# CTRL_MMR0_CFG0 register map
Vendor: Texas Instruments
Registers are 32-bit, read-write, reset 0x0 unless marked. A register's access mark holds for its fields unless they carry their own. Offsets are as the file gives them; [hi:lo] are bit positions; {n}, {i} and the like mark numbered series; 'fields as' and 'values as' point back to an identical list.

## CTRL_MMR0_CFG0 (part 7 of 10)
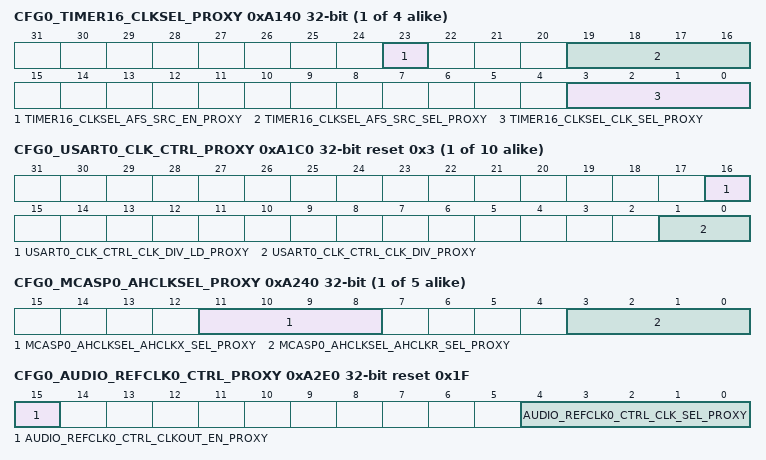
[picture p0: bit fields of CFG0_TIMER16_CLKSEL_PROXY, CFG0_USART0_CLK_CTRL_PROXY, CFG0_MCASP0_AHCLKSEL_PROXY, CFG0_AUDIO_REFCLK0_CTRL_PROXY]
{0xA100+4i} CFG0_TIMER{i}_CLKSEL_PROXY (i=16..19) — Timer{i} functional clock selection control
  [23] TIMER{i}_CLKSEL_AFS_SRC_EN_PROXY — Enable AFS source mux output as the Timer clock source. Note that for TIMER17 and TIMER19 this selection will be overridden if cascade_en in the associated TIMERn_CTRL register is set. 0 - Use functional clock selected by clk_sel value 1 - Use AFS input selected by afs_src_sel value
  [19:16] TIMER{i}_CLKSEL_AFS_SRC_SEL_PROXY — Selects the ASFR/AFSX input to use as a timer clock when afs_src_en is set. Field values (Others are reserved): 4'b0000 - McASP0_AFSR 4'b0001 - McASP0_AFSX 4'b0010 - McASP1_AFSR 4'b0011 - McASP1_AFSX 4'b0100 - McASP2_AFSR 4'b0101 - McASP2_AFSX 4'b0110 - McASP3_AFSR 4'b0111 - McASP3_AFSX 4'b1000 - McASP4_AFSR 4'b1001 - McASP4_AFSX 4'b1010 - 0 4'b1011 - 0 4'b1100 - 0 4'b1101 - 0 4'b1110 - 0 4'b1111 - 0
  [3:0] TIMER{i}_CLKSEL_CLK_SEL_PROXY — Timer functional clock input select mux control (Reserved values default to HFOSC1_CLK) Field values (Others are reserved): 4'b0000 - HFOSC0_CLKOUT 4'b0001 - HFOSC1_CLKOUT 4'b0010 - MAIN_PLL0_HSDIV1_CLKOUT 4'b0011 - CLK_12M_RC 4'b0100 - MAIN_PLL3_HSDIV3_CLKOUT 4'b0101 - MCU_EXT_REFCLK0 (pin) 4'b0110 - EXT_REFCLK1 (pin) 4'b0111 - LFXOSC_CLKOUT 4'b1000 - CPTS_RFT_CLK (pin) 4'b1001 - MAIN_PLL1_HSDIV3_CLKOUT 4'b1010 - MAIN_PLL2_HSDIV6_CLKOUT 4'b1011 - MAIN_PLL4_HSDIV2_CLKOUT 4'b1100 - CPTS_GENF2 4'b1101 - CPTS_GENF3 4'b1110 - CPSW2G_CPTS_GENF0 4'b1111 - CPSW9G_CPTS_GENF0
{0xA190+4i} CFG0_SPI{i}_CLKSEL_PROXY (i=0..3) — SPI{i} clock control
  [16] SPI{i}_CLKSEL_MSTR_LB_CLKSEL_PROXY — Master mode receive capture clock loopback selection 1'b0 - Internal clock loopback 1'b1 - Loopback from pad
{0xA190+4i} CFG0_SPI{i}_CLKSEL_PROXY (i=5..7) — SPI{i} clock control
  fields as CFG0_SPI0_CLKSEL_PROXY
{0xA1C0+4i} CFG0_USART{i}_CLK_CTRL_PROXY reset 0x3 (i=0..9) — Selects the clock divider of the USART{i} functional clock
  [16] USART{i}_CLK_CTRL_CLK_DIV_LD_PROXY — Load the output divider valueWriting 1 to this bit will generate a load pulse to load the USART{i} clock programmable divider value. This bit can be cleared but must not be set in the same write cycle in which the clk_div value is changed.
  [1:0] USART{i}_CLK_CTRL_CLK_DIV_PROXY — Selects the clock divider value. Supports divide values of 1 to 4 Default is /4. To load the new divider value the clk_div_ld bit must be cleared and then set to 1. Field values (Others are reserved): 2'b00 - Divide by 1 2'b01 - Divide by 2 2'b10 - Divide by 3 2'b11 - Divide by 4
{0xA200+4i} CFG0_MCASP{i}_CLKSEL_PROXY (i=0..4) — Selects the functional clock source for McASP{i}
  [2:0] MCASP{i}_CLKSEL_AUXCLK_SEL_PROXY — Selects the McASP{i} auxclk clock source Reserved values default to HFOSC1_CLK Field values (Others are reserved): 3'b000 - MAIN_PLL4_HSDIV0_CLKOUT 3'b001 - MAIN_PLL2_HSDIV2_CLKOUT 3'b010 - 0 3'b011 - 0 3'b100 - ATCLK0 3'b101 - ATCLK1 3'b110 - ATCLK2 3'b111 - ATCLK3
{0xA240+4i} CFG0_MCASP{i}_AHCLKSEL_PROXY (i=0..4) — Selects the AHCLKX and AHCLKR clock source for McASP{i}
  [11:8] MCASP{i}_AHCLKSEL_AHCLKX_SEL_PROXY — Selects the AHCLKX input source for McASP{i} Field values (Others are reserved): 4'b0000 - HFOSC1_CLKOUT 4'b0001 - HFOSC0_CLKOUT 4'b0010 - AUDIO_EXT_REFCLK0_IN 4'b0011 - AUDIO_EXT_REFCLK1_IN 4'b0100 - 0 4'b0101 - 0 4'b0110 - 0 4'b0111 - 0 4'b1000 - ATCLK0 4'b1001 - ATCLK1 4'b1010 - ATCLK2 4'b1011 - ATCLK3
  [3:0] MCASP{i}_AHCLKSEL_AHCLKR_SEL_PROXY — Selects the AHCLKR input source for McASP{i} Field values (Others are reserved): 4'b0000 - HFOSC1_CLKOUT 4'b0001 - HFOSC0_CLKOUT 4'b0010 - AUDIO_EXT_REFCLK0_IN 4'b0011 - AUDIO_EXT_REFCLK1_IN 4'b0100 - 0 4'b0101 - 0 4'b0110 - 0 4'b0111 - 0 4'b1000 - ATCLK0 4'b1001 - ATCLK1 4'b1010 - ATCLK2 4'b1011 - ATCLK3 4'b1100 - 0 4'b1101 - 0 4'b1110 - 0 4'b1111 - 0
{0xA2A0+4i} CFG0_ATL_BWS{i}_SEL_PROXY (i=0..3) — Selects the source of ATL Baseband Word Select {i}
  [4:0] ATL_BWS{i}_SEL_WD_SEL_PROXY — BWS source signal Field values (Others are reserved): 5'b00000 - McASP0 AFSR Pin Input 5'b00001 - McASP1 AFSR Pin Input 5'b00010 - McASP2 AFSR Pin Input 5'b00011 - McASP3 AFSR Pin Input 5'b00100 - McASP4 AFSR Pin Input 5'b00101 - 0 5'b00110 - 0 5'b00111 - 0 5'b01000 - 0 5'b01001 - 0 5'b01010 - 0 5'b01011 - 0 5'b01100 - McASP0 AFSX Pin Input 5'b01101 - McASP1 AFSX Pin Input 5'b01110 - McASP2 AFSX Pin Input 5'b01111 - McASP3 AFSX Pin Input 5'b10000 - McASP4 AFSX Pin Input 5'b10001 - 0 5'b10010 - 0 5'b10011 - 0 5'b10100 - 0 5'b10101 - 0 5'b10110 - 0 5'b10111 - 0 5'b11000 - AUDIO_EXT_REFCLK0 Pin input 5'b11001 - AUDIO_EXT_REFCLK1 Pin input 5'b11010 - 0 5'b11011 - 0
{0xA2B0+4i} CFG0_ATL_AWS{i}_SEL_PROXY (i=0..3) — Selects the source of ATL Audio Word Select {i}
  [4:0] ATL_AWS{i}_SEL_WD_SEL_PROXY — AWS source signal Field values (Others are reserved): 5'b00000 - McASP0 AFSX Pin Input 5'b00001 - McASP1 AFSX Pin Input 5'b00010 - McASP2 AFSX Pin Input 5'b00011 - McASP3 AFSX Pin Input 5'b00100 - McASP4 AFSX Pin Input 5'b00101 - 0 5'b00110 - 0 5'b00111 - 0 5'b01000 - 0 5'b01001 - 0 5'b01010 - 0 5'b01011 - 0 5'b01100 - McASP0 AFSX Pin Input 5'b01101 - McASP1 AFSX Pin Input 5'b01110 - McASP2 AFSX Pin Input 5'b01111 - McASP3 AFSX Pin Input 5'b10000 - McASP4 AFSX Pin Input 5'b10001 - 0 5'b10010 - 0 5'b10011 - 0 5'b10100 - 0 5'b10101 - 0 5'b10110 - 0 5'b10111 - 0 5'b11000 - AUDIO_EXT_REFCLK0 Pin input 5'b11001 - AUDIO_EXT_REFCLK1 Pin input 5'b11010 - 0 5'b11011 - 0 5'b11100 - 0 5'b11101 - 0
0xA2C0 CFG0_ATL_CLKSEL_PROXY — Selects the source of the ATL PCLK
  [3:0] ATL_CLKSEL_PCLK_SEL_PROXY — Selects the PCLK clock source Field values (Others are reserved): 3'b000 - MAIN_PLL4_HSDIV1_CLKOUT 3'b001 - MAIN_PLL2_HSDIV2_CLKOUT 3'b010 - 0 3'b011 - 0 3'b100 - MAIN_PLL0_HSDIV7_CLKOUT 3'b101 - MCU_EXT_REFCLK0 (pin) 3'b110 - EXT_REFCLK1 (pin) 3'b111 - 0
0xA2E0 CFG0_AUDIO_REFCLK0_CTRL_PROXY reset 0x1F — Selects the clock source for the AUDIO_EXT_REFCLK0 output
  [15] AUDIO_REFCLK0_CTRL_CLKOUT_EN_PROXY — AUDIO_REFCLK 0 output enableThis bit is inverted to drive the active low output buffer enable 0 - AUDIO_EXT_REFCLK0 pin is configured as an input 1 - AUDIO_EXT_REFCLK0 pin is configured as an output
  [4:0] AUDIO_REFCLK0_CTRL_CLK_SEL_PROXY — Clock source (default selects a tie-off of 0 for no output) Field values (Others are reserved): 5'b00000 - MCASP0 AHCLKR Output 5'b00001 - MCASP1 AHCLKR Output 5'b00010 - MCASP2 AHCLKR Output 5'b00011 - MCASP3 AHCLKR Output 5'b00100 - MCASP4 AHCLKR Output 5'b01100 - MCASP0 AHCLKX Output 5'b01101 - MCASP1 AHCLKX Output 5'b01110 - MCASP2 AHCLKX Output 5'b01111 - MCASP3 AHCLKX Output 5'b10000 - MCASP4 AHCLKX Output 5'b11000 - ATCLK0 5'b11001 - ATCLK1 5'b11010 - ATCLK2 5'b11011 - ATCLK3 5'b11100 - MAIN_PLL4_HSDIV2_CLKOUT 5'b11101 - 0 5'b11110 - 0 5'b11111 - 0
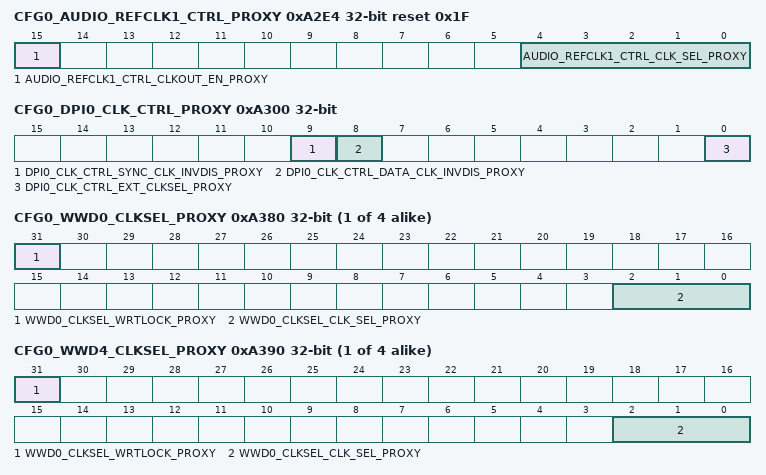
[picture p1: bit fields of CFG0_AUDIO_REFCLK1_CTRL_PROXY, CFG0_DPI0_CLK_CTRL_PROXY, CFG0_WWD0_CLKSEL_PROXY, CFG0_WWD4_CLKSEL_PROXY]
0xA2E4 CFG0_AUDIO_REFCLK1_CTRL_PROXY reset 0x1F — Selects the clock source for the AUDIO_EXT_REFCLK1 output
  [15] AUDIO_REFCLK1_CTRL_CLKOUT_EN_PROXY — AUDIO_REFCLK 1 output enableThis bit is inverted to drive the active low output buffer enable 0 - AUDIO_EXT_REFCLK1 pin is configured as an input 1 - AUDIO_EXT_REFCLK1 pin is configured as an output
  [4:0] AUDIO_REFCLK1_CTRL_CLK_SEL_PROXY — Clock source (default selects a tie-off of 0 for no output) Field values (Others are reserved): 5'b00000 - MCASP0 AHCLKR Output 5'b00001 - MCASP1 AHCLKR Output 5'b00010 - MCASP2 AHCLKR Output 5'b00011 - MCASP3 AHCLKR Output 5'b00100 - MCASP4 AHCLKR Output 5'b01100 - MCASP0 AHCLKX Output 5'b01101 - MCASP1 AHCLKX Output 5'b01110 - MCASP2 AHCLKX Output 5'b01111 - MCASP3 AHCLKX Output 5'b10000 - MCASP4 AHCLKX Output 5'b11000 - ATCLK0 5'b11001 - ATCLK1 5'b11010 - ATCLK2 5'b11011 - ATCLK3 5'b11100 - MAIN_PLL4_HSDIV2_CLKOUT 5'b11101 - 0 5'b11110 - 0 5'b11111 - 0
0xA300 CFG0_DPI0_CLK_CTRL_PROXY — Selects the clock source for the DPI0 video output
  [9] DPI0_CLK_CTRL_SYNC_CLK_INVDIS_PROXY — Clock edge select for DPI0 sync outputs 0 - HSYNC and VSYNC are driven on the falling edge of clk 1 - HSYNC and VSYNC are driven on the rising edge of clkNote that this value should align with the programmed value of the DSS POL_FREQ.RF bitfield.
  [8] DPI0_CLK_CTRL_DATA_CLK_INVDIS_PROXY — Clock edge select for DPI0 data outputs 0 - DATA and DE are driven on the falling edge of clk 1 - DATA and DE are driven on the rising edge of clkNote that this value should align with the programmed value of the DSS POL_FREQ.IPC bitfield.
  [0] DPI0_CLK_CTRL_EXT_CLKSEL_PROXY — Selects whether to use DSS PLL3 or an external pin as a DPI clock source. (See the J7AM Clock Specification for more details.) 0 - Use internal clock : MAIN_PLL19_HSDIV0_CLKOUT 1 - Use external clock : VOUT0_EXTPCLKIN
0xA310 CFG0_DPHY0_CLKSEL_PROXY — Selects the clock source for the DSI0 transmit PHY
  [1:0] DPHY0_CLKSEL_REF_CLK_SEL_PROXY — DPHY reference clock source 2'b00 - HFOSC0_CLKOUT 2'b01 - HFOSC1_CLKOUT 2'b10 - MAIN_PLL3_HSDIV4_CLKOUT 2'b11 - MAIN_PLL2_HSDIV4_CLKOUT
0xA314 CFG0_DPHY1_CLKSEL_PROXY — Selects the clock source for the DSI1 transmit PHY
  [1:0] DPHY1_CLKSEL_REF_CLK_SEL_PROXY — DPHY reference clock source 2'b00 - HFOSC0_CLKOUT 2'b01 - HFOSC1_CLKOUT 2'b10 - MAIN_PLL3_HSDIV4_CLKOUT 2'b11 - MAIN_PLL2_HSDIV4_CLKOUT
0xA324 CFG0_DSS_DISPC0_CLKSEL1_PROXY — Selects the clock source for DPI Lane 1 of Display Controller Instance 0
  [1:0] DSS_DISPC0_CLKSEL1_DPI1_PCLK_PROXY — DPI lane 1 pixel clock source Field values (Others are reserved): 2'b00 - MAIN_PLL17_HSDIV0_CLKOUT 2'b01 - MAIN_PLL19_HSDIV0_CLKOUT_EXTPCLKIN 2'b10 - MAIN_PLL19_HSDIV0_CLKOUT_EXTPCLKIN 2'b11 - MAIN_PLL16_HSDIV0_CLKOUT
0xA328 CFG0_DSS_DISPC0_CLKSEL2_PROXY — Selects the clock source for DPI Lane 2 of Display Controller Instance 0
  [0] DSS_DISPC0_CLKSEL2_DPI2_PCLK_PROXY — DPI lane 2 pixel clock source Field values (Others are reserved): 1'b0 - MAIN_PLL16_HSDIV0_CLKOUT 1'b1 - MAIN_PLL17_HSDIV0_CLKOUT
0xA32C CFG0_DSS_DISPC0_CLKSEL3_PROXY — Can also override the DPI Lane 0 and DPI Lane 2 clock source for certain values.
  [2:0] DSS_DISPC0_CLKSEL3_DPI3_PCLK_PROXY — DPI lane 3 pixel clock sourceNote that values of 3'b1x1 also change the DPI lane 0 pixel clock source and values of 3'b11x change the DPI lane 2 pixel clock source Field values (Others are reserved): 3'b000 - MAIN_PLL16_HSDIV1_CLKOUT 3'b001 - MAIN_PLL17_HSDIV1_CLKOUT 3'b010 - MAIN_PLL17_HSDIV1_CLKOUT 3'b011 - MAIN_PLL19_HSDIV0_CLKOUT_EXTPCLKIN 3'b100 - MAIN_PLL19_HSDIV0_CLKOUT_EXTPCLKIN 3'b101 - MAIN_PLL19_HSDIV0_CLKOUT_EXTPCLKIN and dpi0_pclk = dpi1_pclk 3'b110 - MAIN_PLL19_HSDIV0_CLKOUT_EXTPCLKIN and dpi2_pclk = MAIN_PLL19_HSDIV0_CLKOUT_EXTPCLKIN 3'b111 - MAIN_PLL19_HSDIV0_CLKOUT_EXTPCLKIN and dpi0_pclk = dpi1_pclk and dpi2_pclk = MAIN_PLL19_HSDIV0_CLKOUT_EXTPCLKIN
0xA350 CFG0_EDP0_CLK_CTRL_PROXY — Controls clock operation for Embedded Display Port 0
  [8] EDP0_CLK_CTRL_DSI_CLK_DYN_SWTCH_DIS_PROXY — EDP0 DSI clock dynamic switch disable.This bit controls whether the EDP source clock is dynamically switched (to MAIN_PLL2_HSDIV7_CLKOUT) on a warm reset event. (See PLL Bypass Logic during Main WarmReset details in the Reset MicroArch Specification). This bit only applies if eDP reset isolation is enabled. 0 - Dynamic switching on warm reset is enabled 1 - Dynamic switching on warm reset is disabled
{0xA380+4i} CFG0_WWD{i}_CLKSEL_PROXY (i=0..3) — ARM MPU Cluster 0 Core {i} Windowed watchdog timer functional clock selection control
  [31] WWD{i}_CLKSEL_WRTLOCK_PROXY — When set, locks WWD{i}_CLKSEL from further writes until the next module reset.
  [2:0] WWD{i}_CLKSEL_CLK_SEL_PROXY — Windowed watchdog timer functional clock input select mux control Field values (Others are reserved): 3'b000 - HFOSC0_CLKOUT 3'b001 - LFXOSC_CLKOUT 3'b010 - CLK_12M_RC 3'b011 - CLK_32K 3'b100 - HFOSC1_CLKOUT 3'b101 - reserved (HFOSC1_CLKOUT) 3'b110 - reserved (HFOSC1_CLKOUT) 3'b111 - reserved (HFOSC1_CLKOUT)
{0xA380+4i} CFG0_WWD{i}_CLKSEL_PROXY (i=4..7) — ARM MPU Cluster 1 Core {i-4} Windowed watchdog timer functional clock selection control
  fields as CFG0_WWD0_CLKSEL_PROXY
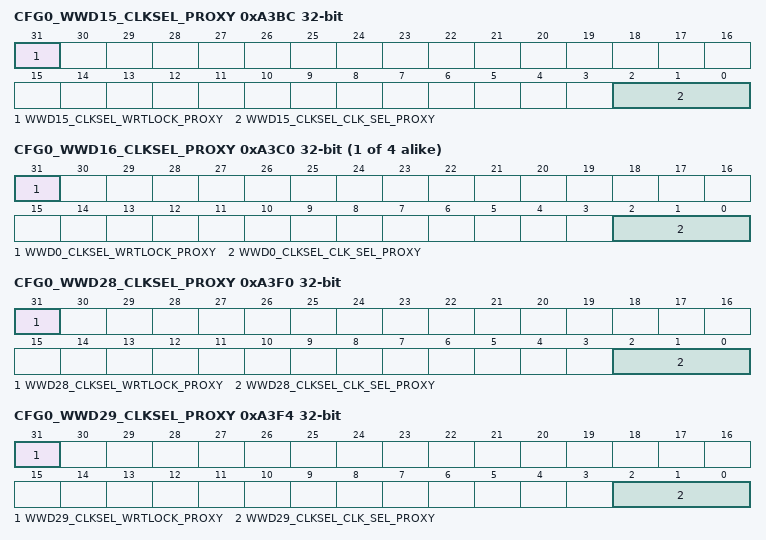
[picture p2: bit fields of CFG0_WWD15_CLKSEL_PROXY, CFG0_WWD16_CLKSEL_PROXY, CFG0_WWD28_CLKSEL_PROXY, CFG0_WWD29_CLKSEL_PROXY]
0xA3BC CFG0_WWD15_CLKSEL_PROXY — GPU Windowed watchdog timer functional clock selection control
  [31] WWD15_CLKSEL_WRTLOCK_PROXY — When set, locks WWD15_CLKSEL from further writes until the next module reset.
  [2:0] WWD15_CLKSEL_CLK_SEL_PROXY — Windowed watchdog timer functional clock input select mux control Field values (Others are reserved): 3'b000 - HFOSC0_CLKOUT 3'b001 - LFXOSC_CLKOUT 3'b010 - CLK_12M_RC 3'b011 - CLK_32K 3'b100 - HFOSC1_CLKOUT 3'b101 - reserved (HFOSC1_CLKOUT) 3'b110 - reserved (HFOSC1_CLKOUT) 3'b111 - reserved (HFOSC1_CLKOUT)
{0xA380+4i} CFG0_WWD{i}_CLKSEL_PROXY (i=16..19) — C71x Core {i-16} Windowed watchdog timer functional clock selection control
  fields as CFG0_WWD0_CLKSEL_PROXY
0xA3F0 CFG0_WWD28_CLKSEL_PROXY — Main R5 Clstr0 Core0 Windowed watchdog timer functional clock selection control.
  [31] WWD28_CLKSEL_WRTLOCK_PROXY — When set, locks WWD28_CLKSEL from further writes until the next module reset.
  [2:0] WWD28_CLKSEL_CLK_SEL_PROXY — Windowed watchdog timer functional clock input select mux controlThese bits are warm reset isolated to preserve R5 RTI clock selection. Field values (Others are reserved): 3'b000 - HFOSC0_CLKOUT 3'b001 - LFXOSC_CLKOUT 3'b010 - CLK_12M_RC 3'b011 - CLK_32K 3'b100 - HFOSC1_CLKOUT 3'b101 - reserved (HFOSC1_CLKOUT) 3'b110 - reserved (HFOSC1_CLKOUT) 3'b111 - reserved (HFOSC1_CLKOUT)
0xA3F4 CFG0_WWD29_CLKSEL_PROXY — Main R5 Clstr0 Core1 Windowed watchdog timer functional clock selection control.
  [31] WWD29_CLKSEL_WRTLOCK_PROXY — When set, locks WWD29_CLKSEL from further writes until the next module reset.
  [2:0] WWD29_CLKSEL_CLK_SEL_PROXY — Windowed watchdog timer functional clock input select mux controlThese bits are warm reset isolated to preserve R5 RTI clock selection. Field values (Others are reserved): 3'b000 - HFOSC0_CLKOUT 3'b001 - LFXOSC_CLKOUT 3'b010 - CLK_12M_RC 3'b011 - CLK_32K 3'b100 - HFOSC1_CLKOUT 3'b101 - reserved (HFOSC1_CLKOUT) 3'b110 - reserved (HFOSC1_CLKOUT) 3'b111 - reserved (HFOSC1_CLKOUT)
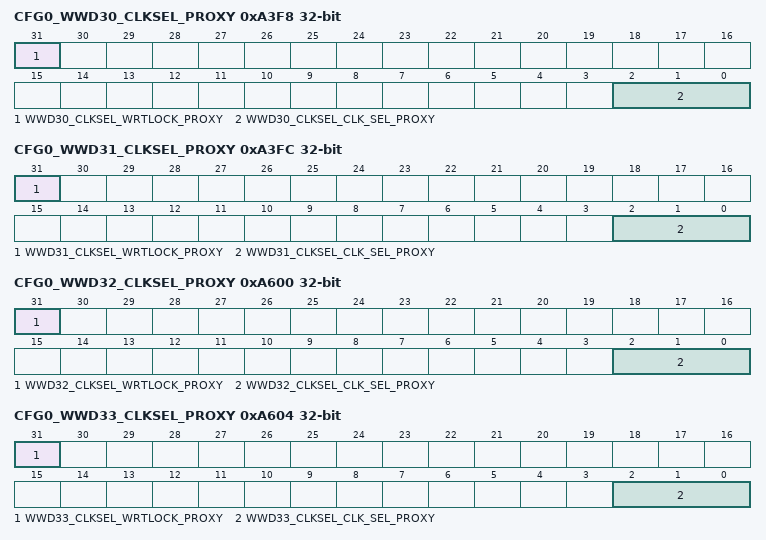
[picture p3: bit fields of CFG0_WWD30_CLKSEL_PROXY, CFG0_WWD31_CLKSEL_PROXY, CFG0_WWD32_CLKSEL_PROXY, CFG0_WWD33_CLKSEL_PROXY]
0xA3F8 CFG0_WWD30_CLKSEL_PROXY — Main R5 Clstr1 Core0 Windowed watchdog timer functional clock selection control.
  [31] WWD30_CLKSEL_WRTLOCK_PROXY — When set, locks WWD30_CLKSEL from further writes until the next module reset.
  [2:0] WWD30_CLKSEL_CLK_SEL_PROXY — Windowed watchdog timer functional clock input select mux controlThese bits are warm reset isolated to preserve R5 RTI clock selection. Field values (Others are reserved): 3'b000 - HFOSC0_CLKOUT 3'b001 - LFXOSC_CLKOUT 3'b010 - CLK_12M_RC 3'b011 - CLK_32K 3'b100 - HFOSC1_CLKOUT 3'b101 - reserved (HFOSC1_CLKOUT) 3'b110 - reserved (HFOSC1_CLKOUT) 3'b111 - reserved (HFOSC1_CLKOUT)
0xA3FC CFG0_WWD31_CLKSEL_PROXY — Main R5 Clstr1 Core1 Windowed watchdog timer functional clock selection control.
  [31] WWD31_CLKSEL_WRTLOCK_PROXY — When set, locks WWD31_CLKSEL from further writes until the next module reset.
  [2:0] WWD31_CLKSEL_CLK_SEL_PROXY — Windowed watchdog timer functional clock input select mux controlThese bits are warm reset isolated to preserve R5 RTI clock selection. Field values (Others are reserved): 3'b000 - HFOSC0_CLKOUT 3'b001 - LFXOSC_CLKOUT 3'b010 - CLK_12M_RC 3'b011 - CLK_32K 3'b100 - HFOSC1_CLKOUT 3'b101 - reserved (HFOSC1_CLKOUT) 3'b110 - reserved (HFOSC1_CLKOUT) 3'b111 - reserved (HFOSC1_CLKOUT)
{0xA400+0x10*i} CFG0_SERDES{i}_CLKSEL_PROXY (i=0..2) — Selects the clock source for Serdes{i}.
  [1:0] SERDES{i}_CLKSEL_CORE_REFCLK_SEL_PROXY — Selects the source for the core_refclk input Field values (Others are reserved): 2'b00 - HFOSC0_CLKOUT 2'b01 - HFOSC1_CLKOUT 2'b10 - MAIN_PLL3_HSDIV4_CLKOUT 2'b11 - MAIN_PLL2_HSDIV4_CLKOUT
0xA440 CFG0_SERDES4_CLKSEL_PROXY — Selects the clock source for Serdes4.
  [1:0] SERDES4_CLKSEL_CORE_REFCLK_SEL_PROXY — Selects the source for the core_refclk input Field values (Others are reserved): 2'b00 - HFOSC0_CLKOUT 2'b01 - HFOSC1_CLKOUT 2'b10 - MAIN_PLL3_HSDIV4_CLKOUT 2'b11 - MAIN_PLL2_HSDIV4_CLKOUT
{0xA480+4i} CFG0_MCAN{i}_CLKSEL_PROXY (i=0..17) — Controls the functional clock source MCAN{i}
  [1:0] MCAN{i}_CLKSEL_CLK_SEL_PROXY — MAIN MCAN_CLK selection 2'b00 - MAIN_PLL0_HSDIV4_CLKOUT 2'b01 - MCU_EXT_REFCLK0 (pin) 2'b10 - HFOSC1_CLKOUT 2'b11 - HFOSC0_CLKOUT
0xA600 CFG0_WWD32_CLKSEL_PROXY — Main R5 Clstr2 Core0 Windowed watchdog timer functional clock selection control.
  [31] WWD32_CLKSEL_WRTLOCK_PROXY — When set, locks WWD32_CLKSEL from further writes until the next module reset.
  [2:0] WWD32_CLKSEL_CLK_SEL_PROXY — Windowed watchdog timer functional clock input select mux controlThese bits are warm reset isolated to preserve R5 RTI clock selection. Field values (Others are reserved): 3'b000 - HFOSC0_CLKOUT 3'b001 - LFXOSC_CLKOUT 3'b010 - CLK_12M_RC 3'b011 - CLK_32K 3'b100 - HFOSC1_CLKOUT 3'b101 - reserved (HFOSC1_CLKOUT) 3'b110 - reserved (HFOSC1_CLKOUT) 3'b111 - reserved (HFOSC1_CLKOUT)
0xA604 CFG0_WWD33_CLKSEL_PROXY — Main R5 Clstr2 Core1 Windowed watchdog timer functional clock selection control.
  [31] WWD33_CLKSEL_WRTLOCK_PROXY — When set, locks WWD33_CLKSEL from further writes until the next module reset.
  [2:0] WWD33_CLKSEL_CLK_SEL_PROXY — Windowed watchdog timer functional clock input select mux controlThese bits are warm reset isolated to preserve R5 RTI clock selection. Field values (Others are reserved): 3'b000 - HFOSC0_CLKOUT 3'b001 - LFXOSC_CLKOUT 3'b010 - CLK_12M_RC 3'b011 - CLK_32K 3'b100 - HFOSC1_CLKOUT 3'b101 - reserved (HFOSC1_CLKOUT) 3'b110 - reserved (HFOSC1_CLKOUT) 3'b111 - reserved (HFOSC1_CLKOUT)
{0xB100+4i} CFG0_CLAIMREG_P2_R{i} (i=0..12)
  [31:0] CLAIMREG_P2_R{i} — Claim bits for Partition 2
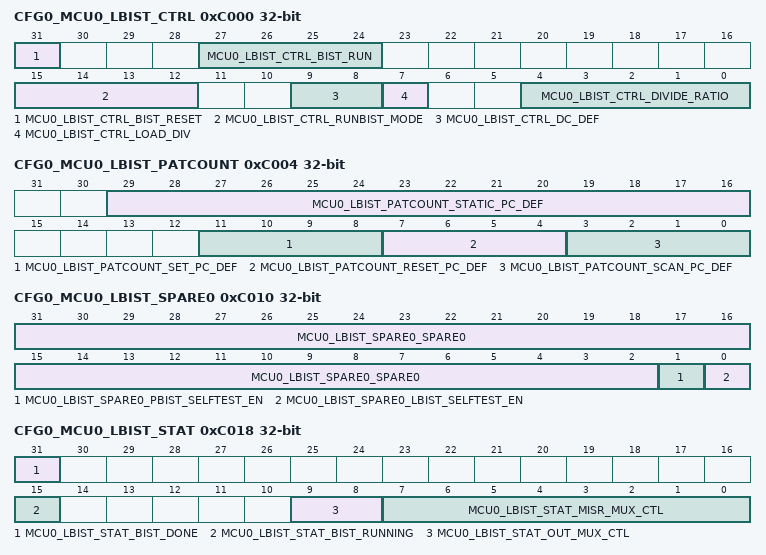
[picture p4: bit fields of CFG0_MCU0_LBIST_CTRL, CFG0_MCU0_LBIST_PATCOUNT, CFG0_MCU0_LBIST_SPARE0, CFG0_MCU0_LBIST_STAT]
0xC000 CFG0_MCU0_LBIST_CTRL — Configures and enables LBIST operation
  [31] MCU0_LBIST_CTRL_BIST_RESET — Reset LBIST macro
  [27:24] MCU0_LBIST_CTRL_BIST_RUN — Starts LBIST if all bits are 1
  [15:12] MCU0_LBIST_CTRL_RUNBIST_MODE — Runbist mode enable if all bits are 1
  [9:8] MCU0_LBIST_CTRL_DC_DEF — Clock delay after scan_enable switching
  [7] MCU0_LBIST_CTRL_LOAD_DIV — Loads LBIST clock divide ratio on transition from 0 to 1
  [4:0] MCU0_LBIST_CTRL_DIVIDE_RATIO — LBIST clock divide ratio
0xC004 CFG0_MCU0_LBIST_PATCOUNT — Specifies the number of LBIST patterns to run
  [29:16] MCU0_LBIST_PATCOUNT_STATIC_PC_DEF — Number of stuck-at patterns to run
  [11:8] MCU0_LBIST_PATCOUNT_SET_PC_DEF — Number of set patterns to run
  [7:4] MCU0_LBIST_PATCOUNT_RESET_PC_DEF — Number of reset patterns to run
  [3:0] MCU0_LBIST_PATCOUNT_SCAN_PC_DEF — Number of chain test patterns to run
0xC008 CFG0_MCU0_LBIST_SEED0 — Specifies the 32 LSBs of the PRPG seed
  [31:0] MCU0_LBIST_SEED0_PRPG_DEF — Initial seed for PRPG (bits 31:0)
0xC00C CFG0_MCU0_LBIST_SEED1 — Specifies the 21 MSBs of the PRPG seed
  [20:0] MCU0_LBIST_SEED1_PRPG_DEF — Initial seed for PRPG (bits 52:32)
0xC010 CFG0_MCU0_LBIST_SPARE0 — Spare LBIST control bits
  [31:2] MCU0_LBIST_SPARE0_SPARE0 — LBIST spare bits
  [1] MCU0_LBIST_SPARE0_PBIST_SELFTEST_EN — PBIST isolation control
  [0] MCU0_LBIST_SPARE0_LBIST_SELFTEST_EN — LBIST isolation control
0xC014 CFG0_MCU0_LBIST_SPARE1 — Spare LBIST control bits
  [31:0] MCU0_LBIST_SPARE1_SPARE1 — LBIST spare bits
0xC018 CFG0_MCU0_LBIST_STAT access per field — Indicates LBIST status and provides MISR selection control
  [31] MCU0_LBIST_STAT_BIST_DONE ro — LBIST is done
  [15] MCU0_LBIST_STAT_BIST_RUNNING ro — LBIST is running
  [9:8] MCU0_LBIST_STAT_OUT_MUX_CTL rw — Selects source of LBIST output 00 - LBIST IP PID value 01 - LBIST CTRL ID value 1x - MISR value
  [7:0] MCU0_LBIST_STAT_MISR_MUX_CTL rw — Selects block of 32 MISR bits to read. A value of 0 selects a compacted 32-bit version of the full MISR. A value of 1-32 select a 32-bit segment of the MISR.
0xC01C CFG0_MCU0_LBIST_MISR ro — Contains LBIST MISR output value
  [31:0] MCU0_LBIST_MISR_MISR_RESULT — 32-bits of MISR value selected by misr_mux_ctl
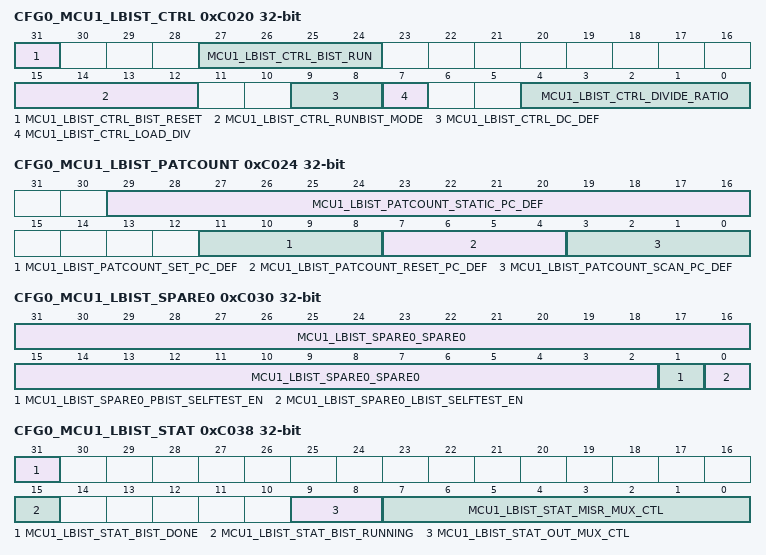
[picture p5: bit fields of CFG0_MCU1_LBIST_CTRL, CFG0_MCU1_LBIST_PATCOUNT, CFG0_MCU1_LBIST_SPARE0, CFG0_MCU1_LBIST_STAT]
0xC020 CFG0_MCU1_LBIST_CTRL — Configures and enables LBIST operation
  [31] MCU1_LBIST_CTRL_BIST_RESET — Reset LBIST macro
  [27:24] MCU1_LBIST_CTRL_BIST_RUN — Starts LBIST if all bits are 1
  [15:12] MCU1_LBIST_CTRL_RUNBIST_MODE — Runbist mode enable if all bits are 1
  [9:8] MCU1_LBIST_CTRL_DC_DEF — Clock delay after scan_enable switching
  [7] MCU1_LBIST_CTRL_LOAD_DIV — Loads LBIST clock divide ratio on transition from 0 to 1
  [4:0] MCU1_LBIST_CTRL_DIVIDE_RATIO — LBIST clock divide ratio
0xC024 CFG0_MCU1_LBIST_PATCOUNT — Specifies the number of LBIST patterns to run
  [29:16] MCU1_LBIST_PATCOUNT_STATIC_PC_DEF — Number of stuck-at patterns to run
  [11:8] MCU1_LBIST_PATCOUNT_SET_PC_DEF — Number of set patterns to run
  [7:4] MCU1_LBIST_PATCOUNT_RESET_PC_DEF — Number of reset patterns to run
  [3:0] MCU1_LBIST_PATCOUNT_SCAN_PC_DEF — Number of chain test patterns to run
0xC028 CFG0_MCU1_LBIST_SEED0 — Specifies the 32 LSBs of the PRPG seed
  [31:0] MCU1_LBIST_SEED0_PRPG_DEF — Initial seed for PRPG (bits 31:0)
0xC02C CFG0_MCU1_LBIST_SEED1 — Specifies the 21 MSBs of the PRPG seed
  [20:0] MCU1_LBIST_SEED1_PRPG_DEF — Initial seed for PRPG (bits 52:32)
0xC030 CFG0_MCU1_LBIST_SPARE0 — Spare LBIST control bits
  [31:2] MCU1_LBIST_SPARE0_SPARE0 — LBIST spare bits
  [1] MCU1_LBIST_SPARE0_PBIST_SELFTEST_EN — PBIST isolation control
  [0] MCU1_LBIST_SPARE0_LBIST_SELFTEST_EN — LBIST isolation control
0xC034 CFG0_MCU1_LBIST_SPARE1 — Spare LBIST control bits
  [31:0] MCU1_LBIST_SPARE1_SPARE1 — LBIST spare bits
0xC038 CFG0_MCU1_LBIST_STAT access per field — Indicates LBIST status and provides MISR selection control
  [31] MCU1_LBIST_STAT_BIST_DONE ro — LBIST is done
  [15] MCU1_LBIST_STAT_BIST_RUNNING ro — LBIST is running
  [9:8] MCU1_LBIST_STAT_OUT_MUX_CTL rw — Selects source of LBIST output 00 - LBIST IP PID value 01 - LBIST CTRL ID value 1x - MISR value
  [7:0] MCU1_LBIST_STAT_MISR_MUX_CTL rw — Selects block of 32 MISR bits to read. A value of 0 selects a compacted 32-bit version of the full MISR. A value of 1-32 select a 32-bit segment of the MISR.
0xC03C CFG0_MCU1_LBIST_MISR ro — Contains LBIST MISR output value
  [31:0] MCU1_LBIST_MISR_MISR_RESULT — 32-bits of MISR value selected by misr_mux_ctl
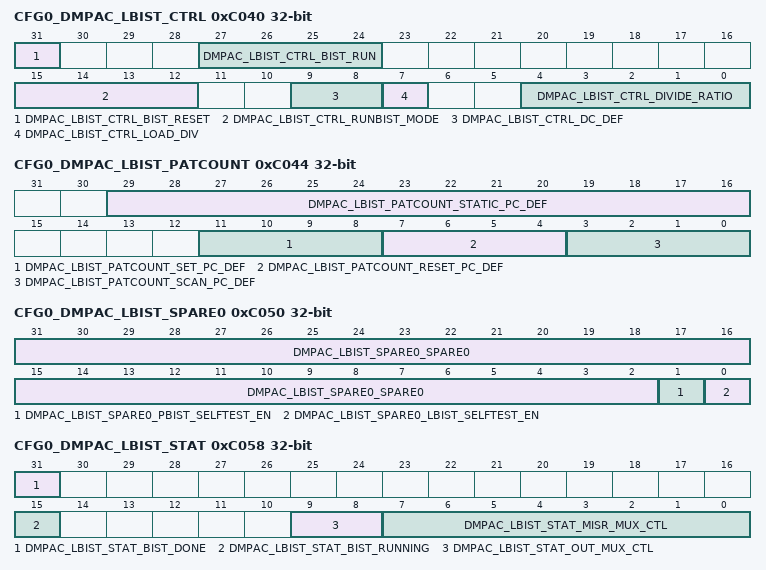
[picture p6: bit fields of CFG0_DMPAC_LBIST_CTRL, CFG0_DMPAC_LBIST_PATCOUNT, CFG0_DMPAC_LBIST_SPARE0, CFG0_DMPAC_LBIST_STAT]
0xC040 CFG0_DMPAC_LBIST_CTRL — Configures and enables LBIST operation
  [31] DMPAC_LBIST_CTRL_BIST_RESET — Reset LBIST macro
  [27:24] DMPAC_LBIST_CTRL_BIST_RUN — Starts LBIST if all bits are 1
  [15:12] DMPAC_LBIST_CTRL_RUNBIST_MODE — Runbist mode enable if all bits are 1
  [9:8] DMPAC_LBIST_CTRL_DC_DEF — Clock delay after scan_enable switching
  [7] DMPAC_LBIST_CTRL_LOAD_DIV — Loads LBIST clock divide ratio on transition from 0 to 1
  [4:0] DMPAC_LBIST_CTRL_DIVIDE_RATIO — LBIST clock divide ratio
0xC044 CFG0_DMPAC_LBIST_PATCOUNT — Specifies the number of LBIST patterns to run
  [29:16] DMPAC_LBIST_PATCOUNT_STATIC_PC_DEF — Number of stuck-at patterns to run
  [11:8] DMPAC_LBIST_PATCOUNT_SET_PC_DEF — Number of set patterns to run
  [7:4] DMPAC_LBIST_PATCOUNT_RESET_PC_DEF — Number of reset patterns to run
  [3:0] DMPAC_LBIST_PATCOUNT_SCAN_PC_DEF — Number of chain test patterns to run
0xC048 CFG0_DMPAC_LBIST_SEED0 — Specifies the 32 LSBs of the PRPG seed
  [31:0] DMPAC_LBIST_SEED0_PRPG_DEF — Initial seed for PRPG (bits 31:0)
0xC04C CFG0_DMPAC_LBIST_SEED1 — Specifies the 21 MSBs of the PRPG seed
  [20:0] DMPAC_LBIST_SEED1_PRPG_DEF — Initial seed for PRPG (bits 52:32)
0xC050 CFG0_DMPAC_LBIST_SPARE0 — Spare LBIST control bits
  [31:2] DMPAC_LBIST_SPARE0_SPARE0 — LBIST spare bits
  [1] DMPAC_LBIST_SPARE0_PBIST_SELFTEST_EN — PBIST isolation control
  [0] DMPAC_LBIST_SPARE0_LBIST_SELFTEST_EN — LBIST isolation control
0xC054 CFG0_DMPAC_LBIST_SPARE1 — Spare LBIST control bits
  [31:0] DMPAC_LBIST_SPARE1_SPARE1 — LBIST spare bits
0xC058 CFG0_DMPAC_LBIST_STAT access per field — Indicates LBIST status and provides MISR selection control
  [31] DMPAC_LBIST_STAT_BIST_DONE ro — LBIST is done
  [15] DMPAC_LBIST_STAT_BIST_RUNNING ro — LBIST is running
  [9:8] DMPAC_LBIST_STAT_OUT_MUX_CTL rw — Selects source of LBIST output 00 - LBIST IP PID value 01 - LBIST CTRL ID value 1x - MISR value
  [7:0] DMPAC_LBIST_STAT_MISR_MUX_CTL rw — Selects block of 32 MISR bits to read. A value of 0 selects a compacted 32-bit version of the full MISR. A value of 1-32 select a 32-bit segment of the MISR.
0xC05C CFG0_DMPAC_LBIST_MISR ro — Contains LBIST MISR output value
  [31:0] DMPAC_LBIST_MISR_MISR_RESULT — 32-bits of MISR value selected by misr_mux_ctl
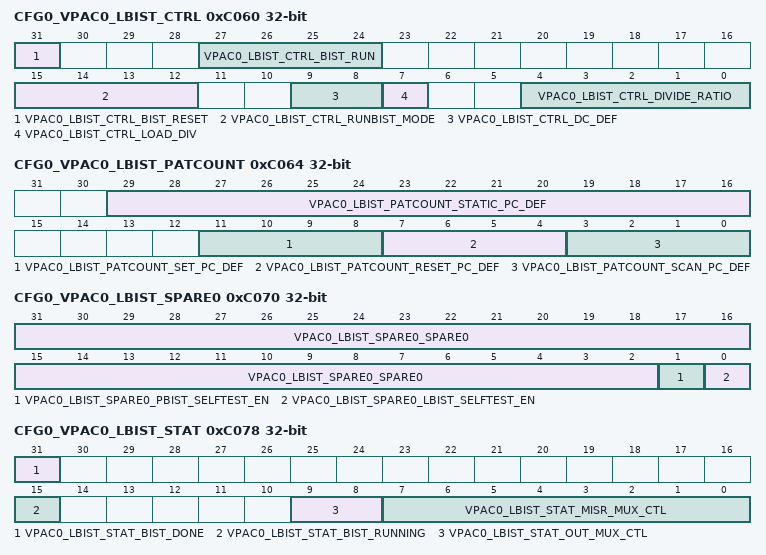
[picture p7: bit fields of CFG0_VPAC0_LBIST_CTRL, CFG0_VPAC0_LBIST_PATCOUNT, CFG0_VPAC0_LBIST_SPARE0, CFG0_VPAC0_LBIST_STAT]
0xC060 CFG0_VPAC0_LBIST_CTRL — Configures and enables LBIST operation
  [31] VPAC0_LBIST_CTRL_BIST_RESET — Reset LBIST macro
  [27:24] VPAC0_LBIST_CTRL_BIST_RUN — Starts LBIST if all bits are 1
  [15:12] VPAC0_LBIST_CTRL_RUNBIST_MODE — Runbist mode enable if all bits are 1
  [9:8] VPAC0_LBIST_CTRL_DC_DEF — Clock delay after scan_enable switching
  [7] VPAC0_LBIST_CTRL_LOAD_DIV — Loads LBIST clock divide ratio on transition from 0 to 1
  [4:0] VPAC0_LBIST_CTRL_DIVIDE_RATIO — LBIST clock divide ratio
0xC064 CFG0_VPAC0_LBIST_PATCOUNT — Specifies the number of LBIST patterns to run
  [29:16] VPAC0_LBIST_PATCOUNT_STATIC_PC_DEF — Number of stuck-at patterns to run
  [11:8] VPAC0_LBIST_PATCOUNT_SET_PC_DEF — Number of set patterns to run
  [7:4] VPAC0_LBIST_PATCOUNT_RESET_PC_DEF — Number of reset patterns to run
  [3:0] VPAC0_LBIST_PATCOUNT_SCAN_PC_DEF — Number of chain test patterns to run
0xC068 CFG0_VPAC0_LBIST_SEED0 — Specifies the 32 LSBs of the PRPG seed
  [31:0] VPAC0_LBIST_SEED0_PRPG_DEF — Initial seed for PRPG (bits 31:0)
0xC06C CFG0_VPAC0_LBIST_SEED1 — Specifies the 21 MSBs of the PRPG seed
  [20:0] VPAC0_LBIST_SEED1_PRPG_DEF — Initial seed for PRPG (bits 52:32)
0xC070 CFG0_VPAC0_LBIST_SPARE0 — Spare LBIST control bits
  [31:2] VPAC0_LBIST_SPARE0_SPARE0 — LBIST spare bits
  [1] VPAC0_LBIST_SPARE0_PBIST_SELFTEST_EN — PBIST isolation control
  [0] VPAC0_LBIST_SPARE0_LBIST_SELFTEST_EN — LBIST isolation control
0xC074 CFG0_VPAC0_LBIST_SPARE1 — Spare LBIST control bits
  [31:0] VPAC0_LBIST_SPARE1_SPARE1 — LBIST spare bits
0xC078 CFG0_VPAC0_LBIST_STAT access per field — Indicates LBIST status and provides MISR selection control
  [31] VPAC0_LBIST_STAT_BIST_DONE ro — LBIST is done
  [15] VPAC0_LBIST_STAT_BIST_RUNNING ro — LBIST is running
  [9:8] VPAC0_LBIST_STAT_OUT_MUX_CTL rw — Selects source of LBIST output 00 - LBIST IP PID value 01 - LBIST CTRL ID value 1x - MISR value
  [7:0] VPAC0_LBIST_STAT_MISR_MUX_CTL rw — Selects block of 32 MISR bits to read. A value of 0 selects a compacted 32-bit version of the full MISR. A value of 1-32 select a 32-bit segment of the MISR.
0xC07C CFG0_VPAC0_LBIST_MISR ro — Contains LBIST MISR output value
  [31:0] VPAC0_LBIST_MISR_MISR_RESULT — 32-bits of MISR value selected by misr_mux_ctl
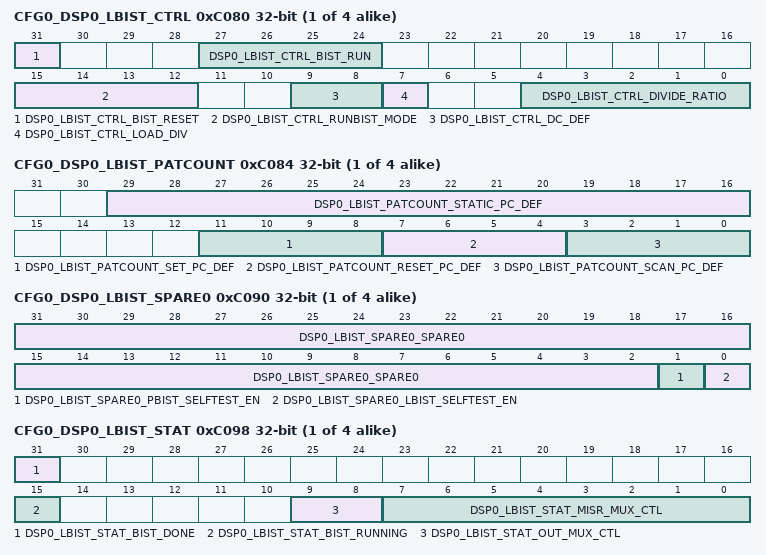
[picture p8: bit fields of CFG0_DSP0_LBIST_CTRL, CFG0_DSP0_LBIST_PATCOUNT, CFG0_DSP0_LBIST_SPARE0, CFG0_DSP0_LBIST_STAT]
{0xC080+0x20*i} CFG0_DSP{i}_LBIST_CTRL (i=0..3) — Configures and enables LBIST operation
  [31] DSP{i}_LBIST_CTRL_BIST_RESET — Reset LBIST macro
  [27:24] DSP{i}_LBIST_CTRL_BIST_RUN — Starts LBIST if all bits are 1
  [15:12] DSP{i}_LBIST_CTRL_RUNBIST_MODE — Runbist mode enable if all bits are 1
  [9:8] DSP{i}_LBIST_CTRL_DC_DEF — Clock delay after scan_enable switching
  [7] DSP{i}_LBIST_CTRL_LOAD_DIV — Loads LBIST clock divide ratio on transition from 0 to 1
  [4:0] DSP{i}_LBIST_CTRL_DIVIDE_RATIO — LBIST clock divide ratio
{0xC084+0x20*i} CFG0_DSP{i}_LBIST_PATCOUNT (i=0..3) — Specifies the number of LBIST patterns to run
  [29:16] DSP{i}_LBIST_PATCOUNT_STATIC_PC_DEF — Number of stuck-at patterns to run
  [11:8] DSP{i}_LBIST_PATCOUNT_SET_PC_DEF — Number of set patterns to run
  [7:4] DSP{i}_LBIST_PATCOUNT_RESET_PC_DEF — Number of reset patterns to run
  [3:0] DSP{i}_LBIST_PATCOUNT_SCAN_PC_DEF — Number of chain test patterns to run
{0xC088+0x20*i} CFG0_DSP{i}_LBIST_SEED0 (i=0..3) — Specifies the 32 LSBs of the PRPG seed
  [31:0] DSP{i}_LBIST_SEED0_PRPG_DEF — Initial seed for PRPG (bits 31:0)
{0xC08C+0x20*i} CFG0_DSP{i}_LBIST_SEED1 (i=0..3) — Specifies the 21 MSBs of the PRPG seed
  [20:0] DSP{i}_LBIST_SEED1_PRPG_DEF — Initial seed for PRPG (bits 52:32)
{0xC090+0x20*i} CFG0_DSP{i}_LBIST_SPARE0 (i=0..3) — Spare LBIST control bits
  [31:2] DSP{i}_LBIST_SPARE0_SPARE0 — LBIST spare bits
  [1] DSP{i}_LBIST_SPARE0_PBIST_SELFTEST_EN — PBIST isolation control
  [0] DSP{i}_LBIST_SPARE0_LBIST_SELFTEST_EN — LBIST isolation control
{0xC094+0x20*i} CFG0_DSP{i}_LBIST_SPARE1 (i=0..3) — Spare LBIST control bits
  [31:0] DSP{i}_LBIST_SPARE1_SPARE1 — LBIST spare bits
{0xC098+0x20*i} CFG0_DSP{i}_LBIST_STAT access per field (i=0..3) — Indicates LBIST status and provides MISR selection control
  [31] DSP{i}_LBIST_STAT_BIST_DONE ro — LBIST is done
  [15] DSP{i}_LBIST_STAT_BIST_RUNNING ro — LBIST is running
  [9:8] DSP{i}_LBIST_STAT_OUT_MUX_CTL rw — Selects source of LBIST output 00 - LBIST IP PID value 01 - LBIST CTRL ID value 1x - MISR value
  [7:0] DSP{i}_LBIST_STAT_MISR_MUX_CTL rw — Selects block of 32 MISR bits to read. A value of 0 selects a compacted 32-bit version of the full MISR. A value of 1-32 select a 32-bit segment of the MISR.
{0xC09C+0x20*i} CFG0_DSP{i}_LBIST_MISR ro (i=0..3) — Contains LBIST MISR output value
  [31:0] DSP{i}_LBIST_MISR_MISR_RESULT — 32-bits of MISR value selected by misr_mux_ctl
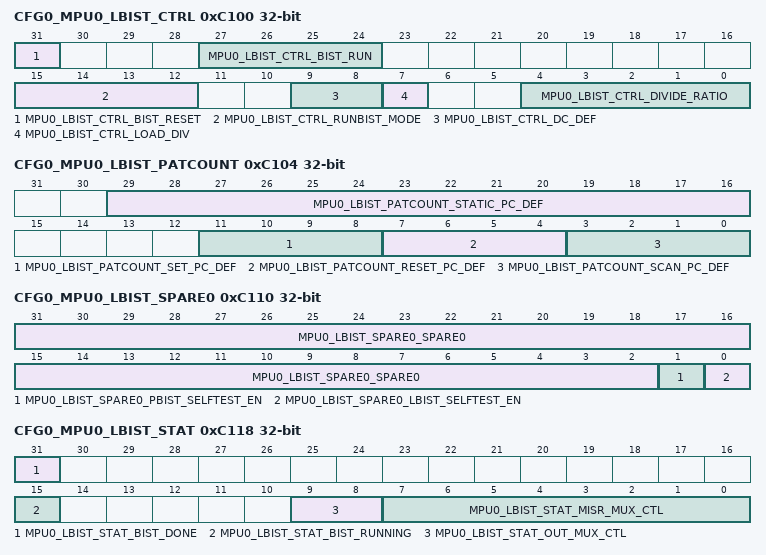
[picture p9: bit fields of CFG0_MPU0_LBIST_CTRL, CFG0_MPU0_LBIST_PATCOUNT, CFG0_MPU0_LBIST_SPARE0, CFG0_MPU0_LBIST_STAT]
0xC100 CFG0_MPU0_LBIST_CTRL — Configures and enables LBIST operation
  [31] MPU0_LBIST_CTRL_BIST_RESET — Reset LBIST macro
  [27:24] MPU0_LBIST_CTRL_BIST_RUN — Starts LBIST if all bits are 1
  [15:12] MPU0_LBIST_CTRL_RUNBIST_MODE — Runbist mode enable if all bits are 1
  [9:8] MPU0_LBIST_CTRL_DC_DEF — Clock delay after scan_enable switching
  [7] MPU0_LBIST_CTRL_LOAD_DIV — Loads LBIST clock divide ratio on transition from 0 to 1
  [4:0] MPU0_LBIST_CTRL_DIVIDE_RATIO — LBIST clock divide ratio
0xC104 CFG0_MPU0_LBIST_PATCOUNT — Specifies the number of LBIST patterns to run
  [29:16] MPU0_LBIST_PATCOUNT_STATIC_PC_DEF — Number of stuck-at patterns to run
  [11:8] MPU0_LBIST_PATCOUNT_SET_PC_DEF — Number of set patterns to run
  [7:4] MPU0_LBIST_PATCOUNT_RESET_PC_DEF — Number of reset patterns to run
  [3:0] MPU0_LBIST_PATCOUNT_SCAN_PC_DEF — Number of chain test patterns to run
0xC108 CFG0_MPU0_LBIST_SEED0 — Specifies the 32 LSBs of the PRPG seed
  [31:0] MPU0_LBIST_SEED0_PRPG_DEF — Initial seed for PRPG (bits 31:0)
0xC10C CFG0_MPU0_LBIST_SEED1 — Specifies the 21 MSBs of the PRPG seed
  [20:0] MPU0_LBIST_SEED1_PRPG_DEF — Initial seed for PRPG (bits 52:32)
0xC110 CFG0_MPU0_LBIST_SPARE0 — Spare LBIST control bits
  [31:2] MPU0_LBIST_SPARE0_SPARE0 — LBIST spare bits
  [1] MPU0_LBIST_SPARE0_PBIST_SELFTEST_EN — PBIST isolation control
  [0] MPU0_LBIST_SPARE0_LBIST_SELFTEST_EN — LBIST isolation control
0xC114 CFG0_MPU0_LBIST_SPARE1 — Spare LBIST control bits
  [31:0] MPU0_LBIST_SPARE1_SPARE1 — LBIST spare bits
0xC118 CFG0_MPU0_LBIST_STAT access per field — Indicates LBIST status and provides MISR selection control
  [31] MPU0_LBIST_STAT_BIST_DONE ro — LBIST is done
  [15] MPU0_LBIST_STAT_BIST_RUNNING ro — LBIST is running
  [9:8] MPU0_LBIST_STAT_OUT_MUX_CTL rw — Selects source of LBIST output 00 - LBIST IP PID value 01 - LBIST CTRL ID value 1x - MISR value
  [7:0] MPU0_LBIST_STAT_MISR_MUX_CTL rw — Selects block of 32 MISR bits to read. A value of 0 selects a compacted 32-bit version of the full MISR. A value of 1-32 select a 32-bit segment of the MISR.
0xC11C CFG0_MPU0_LBIST_MISR ro — Contains LBIST MISR output value
  [31:0] MPU0_LBIST_MISR_MISR_RESULT — 32-bits of MISR value selected by misr_mux_ctl
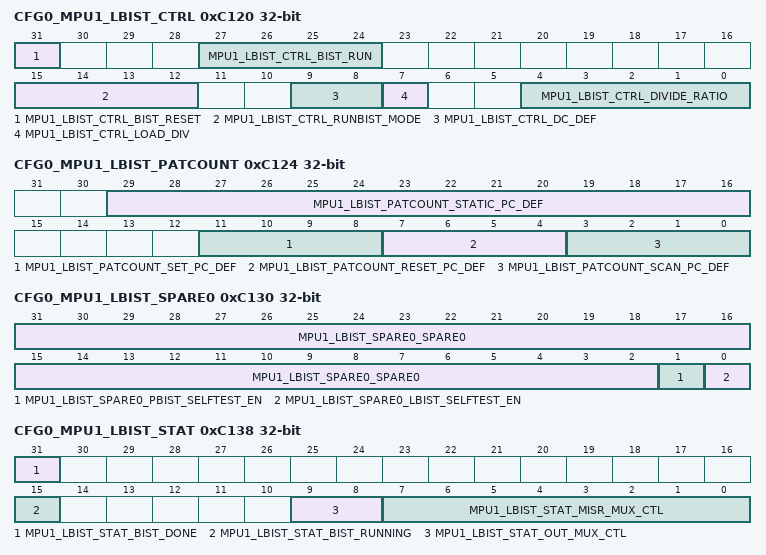
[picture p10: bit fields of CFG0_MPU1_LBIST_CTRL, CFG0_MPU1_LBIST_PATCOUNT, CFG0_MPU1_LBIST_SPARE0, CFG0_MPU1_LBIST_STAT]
0xC120 CFG0_MPU1_LBIST_CTRL — Configures and enables LBIST operation
  [31] MPU1_LBIST_CTRL_BIST_RESET — Reset LBIST macro
  [27:24] MPU1_LBIST_CTRL_BIST_RUN — Starts LBIST if all bits are 1
  [15:12] MPU1_LBIST_CTRL_RUNBIST_MODE — Runbist mode enable if all bits are 1
  [9:8] MPU1_LBIST_CTRL_DC_DEF — Clock delay after scan_enable switching
  [7] MPU1_LBIST_CTRL_LOAD_DIV — Loads LBIST clock divide ratio on transition from 0 to 1
  [4:0] MPU1_LBIST_CTRL_DIVIDE_RATIO — LBIST clock divide ratio
0xC124 CFG0_MPU1_LBIST_PATCOUNT — Specifies the number of LBIST patterns to run
  [29:16] MPU1_LBIST_PATCOUNT_STATIC_PC_DEF — Number of stuck-at patterns to run
  [11:8] MPU1_LBIST_PATCOUNT_SET_PC_DEF — Number of set patterns to run
  [7:4] MPU1_LBIST_PATCOUNT_RESET_PC_DEF — Number of reset patterns to run
  [3:0] MPU1_LBIST_PATCOUNT_SCAN_PC_DEF — Number of chain test patterns to run
0xC128 CFG0_MPU1_LBIST_SEED0 — Specifies the 32 LSBs of the PRPG seed
  [31:0] MPU1_LBIST_SEED0_PRPG_DEF — Initial seed for PRPG (bits 31:0)
0xC12C CFG0_MPU1_LBIST_SEED1 — Specifies the 21 MSBs of the PRPG seed
  [20:0] MPU1_LBIST_SEED1_PRPG_DEF — Initial seed for PRPG (bits 52:32)
0xC130 CFG0_MPU1_LBIST_SPARE0 — Spare LBIST control bits
  [31:2] MPU1_LBIST_SPARE0_SPARE0 — LBIST spare bits
  [1] MPU1_LBIST_SPARE0_PBIST_SELFTEST_EN — PBIST isolation control
  [0] MPU1_LBIST_SPARE0_LBIST_SELFTEST_EN — LBIST isolation control
0xC134 CFG0_MPU1_LBIST_SPARE1 — Spare LBIST control bits
  [31:0] MPU1_LBIST_SPARE1_SPARE1 — LBIST spare bits
0xC138 CFG0_MPU1_LBIST_STAT access per field — Indicates LBIST status and provides MISR selection control
  [31] MPU1_LBIST_STAT_BIST_DONE ro — LBIST is done
  [15] MPU1_LBIST_STAT_BIST_RUNNING ro — LBIST is running
  [9:8] MPU1_LBIST_STAT_OUT_MUX_CTL rw — Selects source of LBIST output 00 - LBIST IP PID value 01 - LBIST CTRL ID value 1x - MISR value
  [7:0] MPU1_LBIST_STAT_MISR_MUX_CTL rw — Selects block of 32 MISR bits to read. A value of 0 selects a compacted 32-bit version of the full MISR. A value of 1-32 select a 32-bit segment of the MISR.
0xC13C CFG0_MPU1_LBIST_MISR ro — Contains LBIST MISR output value
  [31:0] MPU1_LBIST_MISR_MISR_RESULT — 32-bits of MISR value selected by misr_mux_ctl
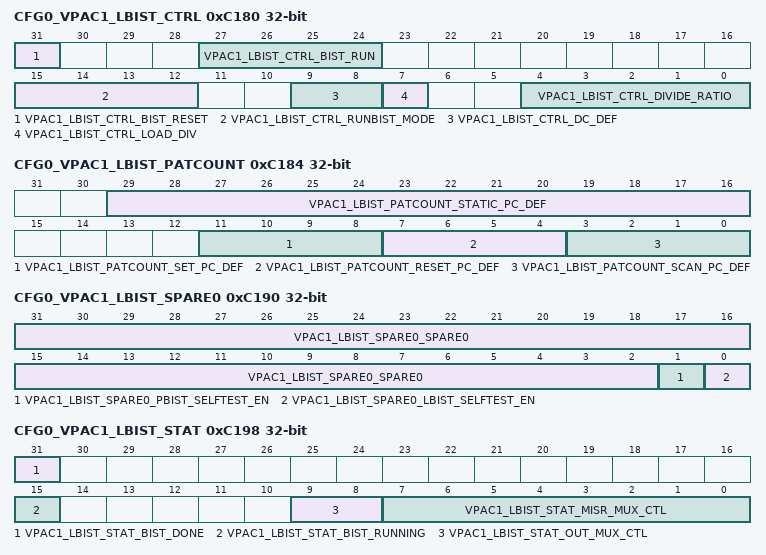
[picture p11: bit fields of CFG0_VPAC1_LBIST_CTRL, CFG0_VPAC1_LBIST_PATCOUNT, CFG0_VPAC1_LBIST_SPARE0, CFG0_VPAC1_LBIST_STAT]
0xC180 CFG0_VPAC1_LBIST_CTRL — Configures and enables LBIST operation
  [31] VPAC1_LBIST_CTRL_BIST_RESET — Reset LBIST macro
  [27:24] VPAC1_LBIST_CTRL_BIST_RUN — Starts LBIST if all bits are 1
  [15:12] VPAC1_LBIST_CTRL_RUNBIST_MODE — Runbist mode enable if all bits are 1
  [9:8] VPAC1_LBIST_CTRL_DC_DEF — Clock delay after scan_enable switching
  [7] VPAC1_LBIST_CTRL_LOAD_DIV — Loads LBIST clock divide ratio on transition from 0 to 1
  [4:0] VPAC1_LBIST_CTRL_DIVIDE_RATIO — LBIST clock divide ratio
0xC184 CFG0_VPAC1_LBIST_PATCOUNT — Specifies the number of LBIST patterns to run
  [29:16] VPAC1_LBIST_PATCOUNT_STATIC_PC_DEF — Number of stuck-at patterns to run
  [11:8] VPAC1_LBIST_PATCOUNT_SET_PC_DEF — Number of set patterns to run
  [7:4] VPAC1_LBIST_PATCOUNT_RESET_PC_DEF — Number of reset patterns to run
  [3:0] VPAC1_LBIST_PATCOUNT_SCAN_PC_DEF — Number of chain test patterns to run
0xC188 CFG0_VPAC1_LBIST_SEED0 — Specifies the 32 LSBs of the PRPG seed
  [31:0] VPAC1_LBIST_SEED0_PRPG_DEF — Initial seed for PRPG (bits 31:0)
0xC18C CFG0_VPAC1_LBIST_SEED1 — Specifies the 21 MSBs of the PRPG seed
  [20:0] VPAC1_LBIST_SEED1_PRPG_DEF — Initial seed for PRPG (bits 52:32)
0xC190 CFG0_VPAC1_LBIST_SPARE0 — Spare LBIST control bits
  [31:2] VPAC1_LBIST_SPARE0_SPARE0 — LBIST spare bits
  [1] VPAC1_LBIST_SPARE0_PBIST_SELFTEST_EN — PBIST isolation control
  [0] VPAC1_LBIST_SPARE0_LBIST_SELFTEST_EN — LBIST isolation control
0xC194 CFG0_VPAC1_LBIST_SPARE1 — Spare LBIST control bits
  [31:0] VPAC1_LBIST_SPARE1_SPARE1 — LBIST spare bits
0xC198 CFG0_VPAC1_LBIST_STAT access per field — Indicates LBIST status and provides MISR selection control
  [31] VPAC1_LBIST_STAT_BIST_DONE ro — LBIST is done
  [15] VPAC1_LBIST_STAT_BIST_RUNNING ro — LBIST is running
  [9:8] VPAC1_LBIST_STAT_OUT_MUX_CTL rw — Selects source of LBIST output 00 - LBIST IP PID value 01 - LBIST CTRL ID value 1x - MISR value
  [7:0] VPAC1_LBIST_STAT_MISR_MUX_CTL rw — Selects block of 32 MISR bits to read. A value of 0 selects a compacted 32-bit version of the full MISR. A value of 1-32 select a 32-bit segment of the MISR.
0xC19C CFG0_VPAC1_LBIST_MISR ro — Contains LBIST MISR output value
  [31:0] VPAC1_LBIST_MISR_MISR_RESULT — 32-bits of MISR value selected by misr_mux_ctl
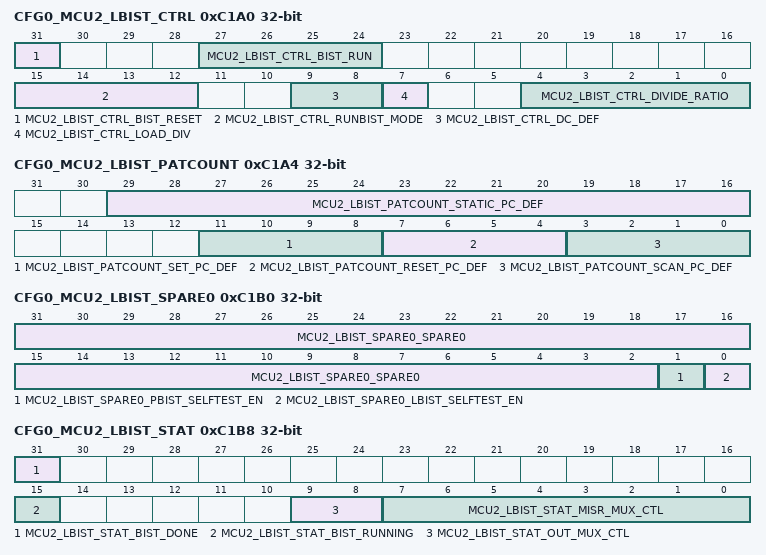
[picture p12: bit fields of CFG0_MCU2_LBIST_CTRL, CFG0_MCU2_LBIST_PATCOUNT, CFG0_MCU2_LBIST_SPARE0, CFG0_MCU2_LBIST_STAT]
0xC1A0 CFG0_MCU2_LBIST_CTRL — Configures and enables LBIST operation
  [31] MCU2_LBIST_CTRL_BIST_RESET — Reset LBIST macro
  [27:24] MCU2_LBIST_CTRL_BIST_RUN — Starts LBIST if all bits are 1
  [15:12] MCU2_LBIST_CTRL_RUNBIST_MODE — Runbist mode enable if all bits are 1
  [9:8] MCU2_LBIST_CTRL_DC_DEF — Clock delay after scan_enable switching
  [7] MCU2_LBIST_CTRL_LOAD_DIV — Loads LBIST clock divide ratio on transition from 0 to 1
  [4:0] MCU2_LBIST_CTRL_DIVIDE_RATIO — LBIST clock divide ratio
0xC1A4 CFG0_MCU2_LBIST_PATCOUNT — Specifies the number of LBIST patterns to run
  [29:16] MCU2_LBIST_PATCOUNT_STATIC_PC_DEF — Number of stuck-at patterns to run
  [11:8] MCU2_LBIST_PATCOUNT_SET_PC_DEF — Number of set patterns to run
  [7:4] MCU2_LBIST_PATCOUNT_RESET_PC_DEF — Number of reset patterns to run
  [3:0] MCU2_LBIST_PATCOUNT_SCAN_PC_DEF — Number of chain test patterns to run
0xC1A8 CFG0_MCU2_LBIST_SEED0 — Specifies the 32 LSBs of the PRPG seed
  [31:0] MCU2_LBIST_SEED0_PRPG_DEF — Initial seed for PRPG (bits 31:0)
0xC1AC CFG0_MCU2_LBIST_SEED1 — Specifies the 21 MSBs of the PRPG seed
  [20:0] MCU2_LBIST_SEED1_PRPG_DEF — Initial seed for PRPG (bits 52:32)
0xC1B0 CFG0_MCU2_LBIST_SPARE0 — Spare LBIST control bits
  [31:2] MCU2_LBIST_SPARE0_SPARE0 — LBIST spare bits
  [1] MCU2_LBIST_SPARE0_PBIST_SELFTEST_EN — PBIST isolation control
  [0] MCU2_LBIST_SPARE0_LBIST_SELFTEST_EN — LBIST isolation control
0xC1B4 CFG0_MCU2_LBIST_SPARE1 — Spare LBIST control bits
  [31:0] MCU2_LBIST_SPARE1_SPARE1 — LBIST spare bits
0xC1B8 CFG0_MCU2_LBIST_STAT access per field — Indicates LBIST status and provides MISR selection control
  [31] MCU2_LBIST_STAT_BIST_DONE ro — LBIST is done
  [15] MCU2_LBIST_STAT_BIST_RUNNING ro — LBIST is running
  [9:8] MCU2_LBIST_STAT_OUT_MUX_CTL rw — Selects source of LBIST output 00 - LBIST IP PID value 01 - LBIST CTRL ID value 1x - MISR value
  [7:0] MCU2_LBIST_STAT_MISR_MUX_CTL rw — Selects block of 32 MISR bits to read. A value of 0 selects a compacted 32-bit version of the full MISR. A value of 1-32 select a 32-bit segment of the MISR.
0xC1BC CFG0_MCU2_LBIST_MISR ro — Contains LBIST MISR output value
  [31:0] MCU2_LBIST_MISR_MISR_RESULT — 32-bits of MISR value selected by misr_mux_ctl
0xC280 CFG0_MCU0_LBIST_SIG ro — Contains expected MISR output value
  [31:0] MCU0_LBIST_SIG_MISR_SIG — MISR signature
0xC284 CFG0_MCU1_LBIST_SIG ro — Contains expected MISR output value
  [31:0] MCU1_LBIST_SIG_MISR_SIG — MISR signature
0xC288 CFG0_DMPAC_LBIST_SIG ro — Contains expected MISR output value
  [31:0] DMPAC_LBIST_SIG_MISR_SIG — MISR signature
0xC28C CFG0_VPAC0_LBIST_SIG ro — Contains expected MISR output value
  [31:0] VPAC0_LBIST_SIG_MISR_SIG — MISR signature
{0xC290+4i} CFG0_DSP{i}_LBIST_SIG ro (i=0..3) — Contains expected MISR output value
  [31:0] DSP{i}_LBIST_SIG_MISR_SIG — MISR signature
0xC2A0 CFG0_MPU0_LBIST_SIG ro — Contains expected MISR output value
  [31:0] MPU0_LBIST_SIG_MISR_SIG — MISR signature
0xC2A4 CFG0_MPU1_LBIST_SIG ro — Contains expected MISR output value
  [31:0] MPU1_LBIST_SIG_MISR_SIG — MISR signature
0xC2B0 CFG0_VPAC1_LBIST_SIG ro — Contains expected MISR output value
  [31:0] VPAC1_LBIST_SIG_MISR_SIG — MISR signature
0xC2C0 CFG0_MCU2_LBIST_SIG ro — Contains expected MISR output value
  [31:0] MCU2_LBIST_SIG_MISR_SIG — MISR signature
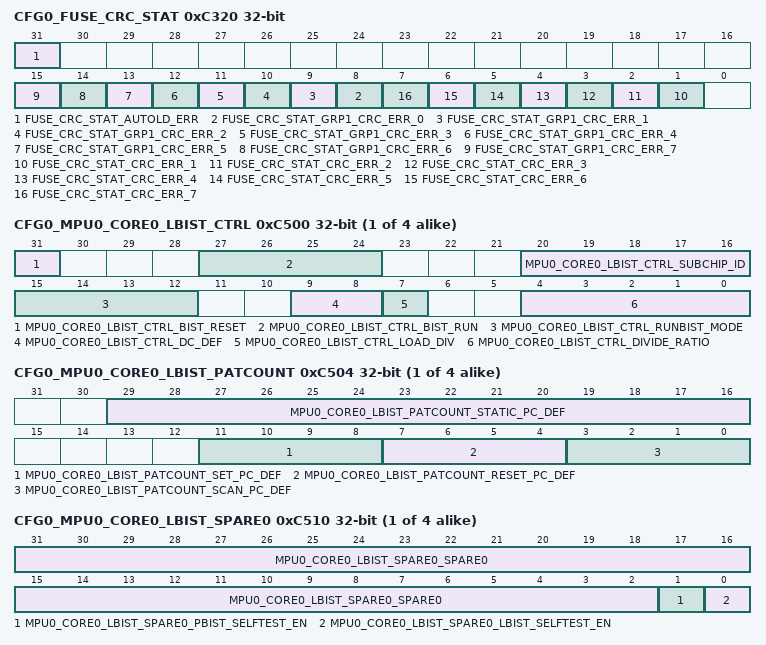
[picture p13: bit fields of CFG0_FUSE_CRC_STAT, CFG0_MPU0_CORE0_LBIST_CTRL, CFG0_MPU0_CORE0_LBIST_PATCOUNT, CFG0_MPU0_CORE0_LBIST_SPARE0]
0xC320 CFG0_FUSE_CRC_STAT ro — Indicates status of fuse chain CRC
  [31] FUSE_CRC_STAT_AUTOLD_ERR — Indicates eFuse autoload or programmation error on any chain
  [n+8] FUSE_CRC_STAT_GRP1_CRC_ERR_{n} (n=0..7) — Indicates eFuse CRC error on group1 chain {n}
  [n] FUSE_CRC_STAT_CRC_ERR_{n} (n=1..7) — Indicates eFuse CRC error on chain {n}
{0xC500+0x20*i} CFG0_MPU0_CORE{i}_LBIST_CTRL (i=0..3) — Configures and enables LBIST operation
  [31] MPU0_CORE{i}_LBIST_CTRL_BIST_RESET — Reset LBIST macro
  [27:24] MPU0_CORE{i}_LBIST_CTRL_BIST_RUN — Starts LBIST if all bits are 1
  [20:16] MPU0_CORE{i}_LBIST_CTRL_SUBCHIP_ID — Specifies which sub-chip is to be tested
  [15:12] MPU0_CORE{i}_LBIST_CTRL_RUNBIST_MODE — Runbist mode enable if all bits are 1
  [9:8] MPU0_CORE{i}_LBIST_CTRL_DC_DEF — Clock delay after scan_enable switching
  [7] MPU0_CORE{i}_LBIST_CTRL_LOAD_DIV — Loads LBIST clock divide ratio on transition from 0 to 1
  [4:0] MPU0_CORE{i}_LBIST_CTRL_DIVIDE_RATIO — LBIST clock divide ratio
{0xC504+0x20*i} CFG0_MPU0_CORE{i}_LBIST_PATCOUNT (i=0..3) — Specifies the number of LBIST patterns to run
  [29:16] MPU0_CORE{i}_LBIST_PATCOUNT_STATIC_PC_DEF — Number of stuck-at patterns to run
  [11:8] MPU0_CORE{i}_LBIST_PATCOUNT_SET_PC_DEF — Number of set patterns to run
  [7:4] MPU0_CORE{i}_LBIST_PATCOUNT_RESET_PC_DEF — Number of reset patterns to run
  [3:0] MPU0_CORE{i}_LBIST_PATCOUNT_SCAN_PC_DEF — Number of chain test patterns to run
{0xC508+0x20*i} CFG0_MPU0_CORE{i}_LBIST_SEED0 (i=0..3) — Specifies the 32 LSBs of the PRPG seed
  [31:0] MPU0_CORE{i}_LBIST_SEED0_PRPG_DEF — Initial seed for PRPG (bits 31:0)
{0xC50C+0x20*i} CFG0_MPU0_CORE{i}_LBIST_SEED1 (i=0..3) — Specifies the 21 MSBs of the PRPG seed
  [20:0] MPU0_CORE{i}_LBIST_SEED1_PRPG_DEF — Initial seed for PRPG (bits 52:32)
{0xC510+0x20*i} CFG0_MPU0_CORE{i}_LBIST_SPARE0 (i=0..3) — Spare LBIST control bits
  [31:2] MPU0_CORE{i}_LBIST_SPARE0_SPARE0 — LBIST spare bits
  [1] MPU0_CORE{i}_LBIST_SPARE0_PBIST_SELFTEST_EN — PBIST isolation control
  [0] MPU0_CORE{i}_LBIST_SPARE0_LBIST_SELFTEST_EN — LBIST isolation control
{0xC514+0x20*i} CFG0_MPU0_CORE{i}_LBIST_SPARE1 (i=0..3) — Spare LBIST control bits
  [31:0] MPU0_CORE{i}_LBIST_SPARE1_SPARE1 — LBIST spare bits
